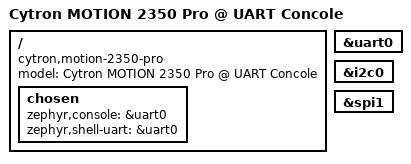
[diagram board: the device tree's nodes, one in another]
/*
 * Copyright (c) 2026 TiaC Systems
 * SPDX-License-Identifier: Apache-2.0
 */

/ {
	model = "Cytron MOTION 2350 Pro @ UART Concole";
	compatible = "cytron,motion-2350-pro",
		     "cytron,motion-2350-pro-uartcons";

	chosen {
		zephyr,console = &uart0;
		zephyr,shell-uart = &uart0;
	};
};

#include "cytron_motion_2350-pro.dtsi"
#include "cytron_motion_2350-2mb.dtsi"

#include "motion_2350_buzzer.dtsi"

#include "motion_2350_pro_button.dtsi"
#include "motion_2350_pro_led_mono.dtsi"
#include "motion_2350_pro_led_ws2812.dtsi"

#include "motion_2350_pro_servo.dtsi"

#include "motion_2350_pro_grove_connectors.dtsi"

grove_serial: &uart0 {};
grove_i2c: &i2c0 {};
grove_spi: &spi1 {};
